# synthetic register map
File version: 1.0
synthetic USART1, generated by SiliconTruth
Registers are 32-bit, read-write, reset 0x0 unless marked. A register's access mark holds for its fields unless they carry their own. Offsets are from the block's base; lines under a group give offsets from that group; [hi:lo] are bit positions; {n}, {i} and the like mark numbered series; 'fields as' and 'values as' point back to an identical list; <NAME> marks a mode.

## Memory map
0x40011000 USART1 size 0x4 — USART1 peripheral

## USART1 — USART1 peripheral
Base 0x40011000
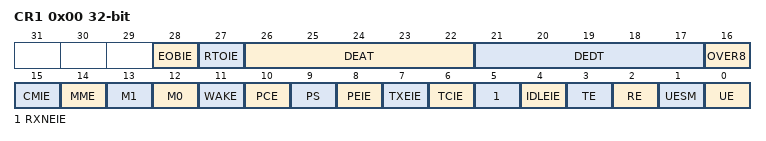
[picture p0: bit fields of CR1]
0x00 CR1
  [28] EOBIE — End of Block interrupt enable.
  [27] RTOIE — Receiver timeout interrupt enable.
  [26:22] DEAT — Driver Enable assertion time.
  [21:17] DEDT — Driver Enable de-assertion time.
  [16] OVER8 — Oversampling mode.
  [15] CMIE — Character match interrupt enable.
  [14] MME — Mute mode enable.
  [13] M1 — Word length.
  [12] M0 — Word length.
  [11] WAKE — Receiver wakeup method.
  [10] PCE — Parity control enable.
  [9] PS — Parity selection.
  [8] PEIE — PE interrupt enable.
  [7] TXEIE — TXE interrupt enable.
  [6] TCIE — Transmission complete interrupt enable.
  [5] RXNEIE — RXNE interrupt enable.
  [4] IDLEIE — IDLE interrupt enable.
  [3] TE — Transmitter enable.
  [2] RE — Receiver enable.
  [1] UESM — USART enable in Stop mode.
  [0] UE — USART enable.
